VERSION ""

NS_ :

BS_:

BU_: XXX

BO_ 2024 NEW_MSG_1: 8 XXX
 SG_ NEW_SIGNAL_1 : 39|11@0+ (1,0) [0|255] "" XXX

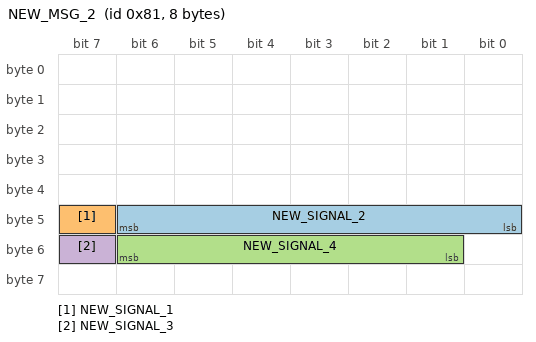
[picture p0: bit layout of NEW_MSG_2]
BO_ 129 NEW_MSG_2: 8 XXX
 SG_ NEW_SIGNAL_2 : 46|7@0+ (1,0) [0|127] "" XXX
 SG_ NEW_SIGNAL_1 : 47|1@0+ (1,0) [0|700000000000] "" XXX
 SG_ NEW_SIGNAL_4 : 54|6@0+ (1,0) [0|127] "" XXX
 SG_ NEW_SIGNAL_3 : 55|1@0+ (1,0) [0|255] "" XXX

BO_ 533 NEW_MSG_3: 8 XXX
 SG_ NEW_SIGNAL_1 : 4|8@0+ (1,0) [0|255] "" XXX

BO_ 336 No changes: 8 XXX

BO_ 352 NEW_MSG_4: 8 XXX
 SG_ NEW_SIGNAL_1 : 14|7@0- (1,0) [0|255] "" XXX
 SG_ NEW_SIGNAL_2 : 34|9@0+ (1,0) [0|65535] "" XXX

BO_ 295 NEW_MSG_5: 8 XXX
 SG_ NEW_SIGNAL_1 : 31|14@0+ (1,0) [0|63] "" XXX

BO_ 296 NEW_MSG_6: 8 XXX
 SG_ NEW_SIGNAL_1 : 7|16@0+ (1,0) [0|255] "" XXX

BO_ 357 NEW_MSG_7: 8 XXX
 SG_ NEW_SIGNAL_1 : 63|9@0+ (1,0) [0|255] "" XXX

BO_ 368 NEW_MSG_8: 8 XXX
 SG_ NEW_SIGNAL_1 : 47|8@0+ (1,0) [0|255] "" XXX

BO_ 512 NEW_MSG_9: 8 XXX
 SG_ NEW_SIGNAL_1 : 4|11@0+ (1,0) [0|65535] "" XXX
